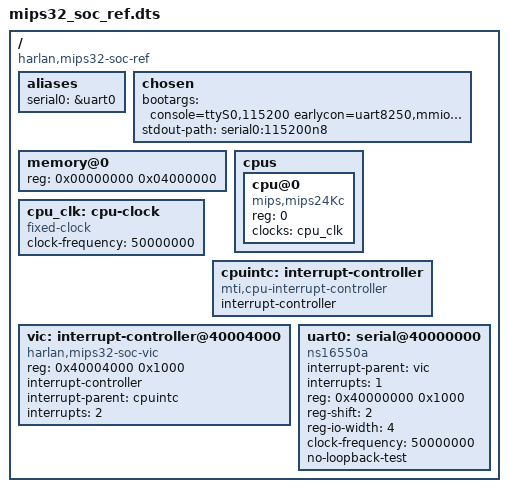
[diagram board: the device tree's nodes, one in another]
// SPDX-License-Identifier: GPL-2.0-or-later
/dts-v1/;

/ {
	#address-cells = <1>;
	#size-cells = <1>;
	compatible = "harlan,mips32-soc-ref";

	aliases { serial0 = &uart0; };
	chosen {
		bootargs = "console=ttyS0,115200 earlycon=uart8250,mmio32,0x40000000 lpj=624128 rdinit=/init";
		stdout-path = "serial0:115200n8";
	};
	memory@0 { device_type = "memory"; reg = <0x00000000 0x04000000>; };

	cpus {
		#address-cells = <1>;
		#size-cells = <0>;
		cpu@0 {
			compatible = "mips,mips24Kc";
			device_type = "cpu";
			reg = <0>;
			clocks = <&cpu_clk>;
		};
	};
	cpu_clk: cpu-clock {
		compatible = "fixed-clock";
		#clock-cells = <0>;
		clock-frequency = <50000000>;
	};
	cpuintc: interrupt-controller {
		#address-cells = <0>;
		#interrupt-cells = <1>;
		interrupt-controller;
		compatible = "mti,cpu-interrupt-controller";
	};
	vic: interrupt-controller@40004000 {
		compatible = "harlan,mips32-soc-vic";
		reg = <0x40004000 0x1000>;
		interrupt-controller;
		#interrupt-cells = <1>;
		interrupt-parent = <&cpuintc>;
		interrupts = <2>;
	};
	uart0: serial@40000000 {
		compatible = "ns16550a";
		interrupt-parent = <&vic>;
		/* UART aggregate is VIC source 1, then CPU Cause.IP2. */
		interrupts = <1>;
		reg = <0x40000000 0x1000>;
		reg-shift = <2>;
		reg-io-width = <4>;
		clock-frequency = <50000000>;
		no-loopback-test;
		status = "okay";
	};
};
